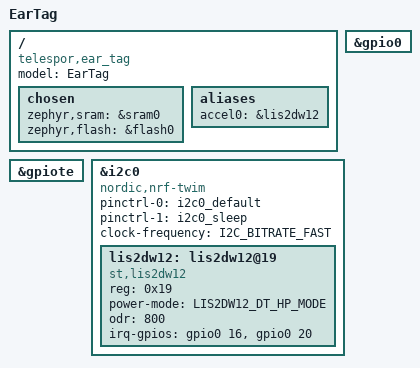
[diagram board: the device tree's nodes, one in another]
/dts-v1/;
#include <nordic/nrf52811_qfaa.dtsi>
#include <zephyr/dt-bindings/sensor/lis2dw12.h>
#include "eartag-pinctrl.dtsi"

/ {
    model = "EarTag";
    compatible = "telespor,ear_tag";

    chosen {
        zephyr,sram = &sram0;
        zephyr,flash = &flash0;
    };

    aliases {
        accel0 = &lis2dw12;
    };
};

&gpio0 {
    status = "okay";
};

&gpiote {
    status = "okay";
};


&i2c0 {
    compatible = "nordic,nrf-twim";
    status = "okay";
    pinctrl-0 = <&i2c0_default>;
    pinctrl-1 = <&i2c0_sleep>;
    pinctrl-names = "default", "sleep";
    clock-frequency = <I2C_BITRATE_FAST>;

    lis2dw12: lis2dw12@19 {
        compatible = "st,lis2dw12";
        reg = <0x19>;
        status = "okay";
        power-mode = <LIS2DW12_DT_HP_MODE>;
        odr = <800>; /* Max sample rate for interrupt mode */
        irq-gpios = <&gpio0 16 (GPIO_ACTIVE_HIGH)>,
                    <&gpio0 20 (GPIO_ACTIVE_HIGH)>;
    };
};
